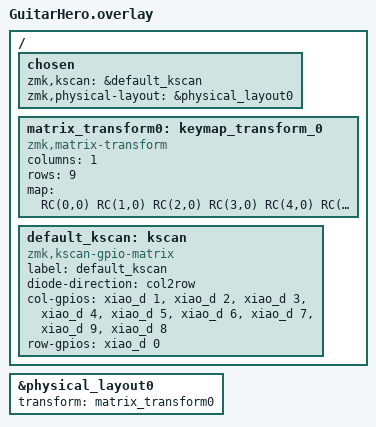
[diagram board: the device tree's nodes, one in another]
/*
 * Copyright (c) 2022 The ZMK Contributors
 *
 * SPDX-License-Identifier: MIT
 */

#include <dt-bindings/zmk/matrix_transform.h>
#include "GuitarHero-layouts.dtsi"

&physical_layout0 {
    transform = <&matrix_transform0>;
};

/ {
    chosen {
        zmk,kscan = &default_kscan;
        zmk,physical-layout = &physical_layout0;
    };

    matrix_transform0: keymap_transform_0 {
        compatible = "zmk,matrix-transform";
        columns = <1>;
        rows = <9>;
        map = <RC(0,0) RC(1,0) RC(2,0) RC(3,0) RC(4,0) RC(5,0) RC(6,0) RC(7,0) RC(8,0)>;
    };


    default_kscan: kscan {
        compatible = "zmk,kscan-gpio-matrix";
        label = "default_kscan";
        diode-direction = "col2row";

        col-gpios = <&xiao_d 1 GPIO_ACTIVE_HIGH>,
            <&xiao_d 2 GPIO_ACTIVE_HIGH>,
            <&xiao_d 3 GPIO_ACTIVE_HIGH>,
            <&xiao_d 4 GPIO_ACTIVE_HIGH>,
            <&xiao_d 5 GPIO_ACTIVE_HIGH>,
            <&xiao_d 6 GPIO_ACTIVE_HIGH>,
            <&xiao_d 7 GPIO_ACTIVE_HIGH>,
            <&xiao_d 9 GPIO_ACTIVE_HIGH>,
            <&xiao_d 8 GPIO_ACTIVE_HIGH>;
        
        row-gpios = <&xiao_d 0 (GPIO_ACTIVE_HIGH | GPIO_PULL_DOWN)>;

    };
};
